# GD32C231 register map
File version: 1.0
GD32C231 ARM 32-bit Cortex-M23 Microcontroller based device
CPU: CM23 r0p0, little endian, MPU, FPU, 4 interrupt priority bits
Registers are 32-bit, read-write, reset 0x0 unless marked. A register's access mark holds for its fields unless they carry their own. Offsets are from the block's base; lines under a group give offsets from that group; [hi:lo] are bit positions; {n}, {i} and the like mark numbered series; 'fields as' and 'values as' point back to an identical list; <NAME> marks a mode.

## Memory map
0x40000400 TIMER2 size 0x400 — General-level0-timers
0x40002000 TIMER13 size 0x400 — General-level0-timers
0x40002800 RTC size 0x400 — Real time clock
0x40002C00 WWDGT size 0x400 — Window watchdog timer
0x40003000 FWDGT size 0x400 — free watchdog timer
0x40003800 SPI1 size 0x400 — Serial peripheral interface
0x40004400 USART1 size 0x400 — Universal synchronous asynchronous receiver transmitter
0x40004800 USART2 size 0x400 — Universal synchronous asynchronous receiver transmitter
0x40005400 I2C0 size 0x400 — Inter integrated circuit
0x40005800 I2C1 size 0x400
0x40007000 PMU size 0x400 — Power management unit
0x40010000 SYSCFG size 0x400 — System and memory architectur
0x40010400 EXTI size 0x400 — Interrupt / event controller
0x40012400 ADC size 0x400 — Analog-to-digital converter
0x40012C00 TIMER0 size 0x400 — Advanced-timers
0x40013000 SPI0 size 0x400 — Serial Peripheral Interface 0
0x40013800 USART0 size 0x400 — Universal synchronous asynchronous receiver transmitter
0x40014400 TIMER15 size 0x400 — General-level4-timers
0x40014800 TIMER16 size 0x400
0x40015800 DBGMCU size 0x400 — Debug support
0x40017C00 CMP size 0x400 — Comparator
0x40020000 DMA size 0x400 — DMA controller
0x40020800 DMAMUX size 0x400 — DMAMUX controller
0x40021000 RCU size 0x400 — Reset and clock unit
0x40022000 FMC size 0x400 — Flash memory controller
0x40023000 CRC size 0x400 — Cyclic redundancy checks management unit
0x48000000 GPIOA size 0x400 — General-purpose I/Os
0x48000400 GPIOB size 0x400 — General-purpose I/Os
0x48000800 GPIOC size 0x400
0x48000C00 GPIOD size 0x400
0x48001400 GPIOF size 0x400
0xE000E100 NVIC size 0xF00 — Nested Vectored Interrupt Controller

## Interrupts
0 WWDGT
1 RTC_Tamper_Timestamp (RTC)
2 RTC_WAKE (RTC)
3 FMC_GLOBAL (FMC)
4 RCU_CTC (RCU)
5 EXTI0 (EXTI)
6 EXTI01 (EXTI)
7 EXTI2 (EXTI)
8 EXTI3 (EXTI)
9 EXTI4 (EXTI)
10 DMA_Channel0 (DMA)
11 DMA_Channel1 (DMA)
12 DMA_Channel2 (DMA)
13 ADC
14 USART0
15 USART1
16 USART2
17 I2C0_EV (I2C0)
18 I2C0_ER (I2C0)
19 I2C1_EV (I2C1)
20 I2C1_ER (I2C1)
21 SPI0
22 SPI1
23 RTC_Alarm (RTC)
24 EXTI5_9 (EXTI)
25 TIMER0_TRIG_UP_BREAK (TIMER0)
26 TIMER0_CAP (TIMER0)
27 TIMER2
28 TIMER13
29 TIMER15
30 TIMER16
31 EXTI10_15 (EXTI)
33 DMA_MUX (DMAMUX)
34 CMP0 (CMP)
35 CMP1 (CMP)
36 I2C0_WAKE (I2C0)
37 I2C1_WAKE (I2C1)
38 USART0_WAKE (USART0)

## ADC — Analog-to-digital converter
Base 0x40012400
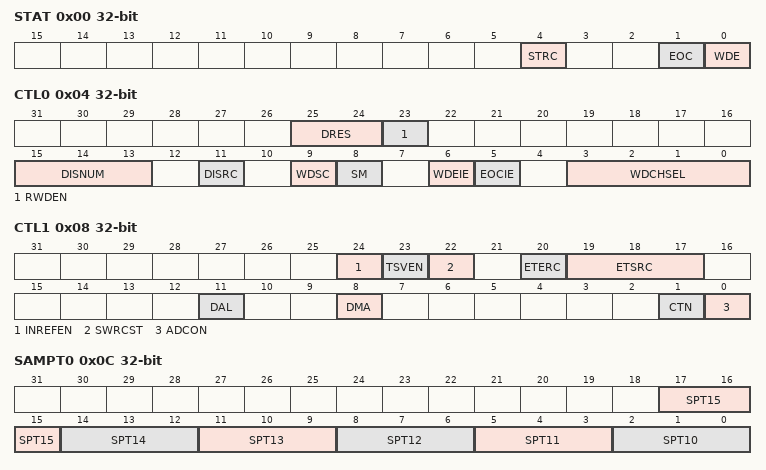
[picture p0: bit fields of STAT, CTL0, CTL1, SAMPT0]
0x00 STAT — Status register
  [4] STRC — Start flag of routine sequence
  [1] EOC — End flag of sequence conversion
  [0] WDE — Analog watchdog event flag
0x04 CTL0 — Control register 0
  [25:24] DRES — ADC resolution
  [23] RWDEN — Routine channel analog watchdog enable
  [15:13] DISNUM — Number of conversions in discontinuous mode
  [11] DISRC — Discontinuous mode on routine sequence
  [9] WDSC — When in scan mode, analog watchdog is effective on a single channel.
  [8] SM — Scan mode
  [6] WDEIE — Interrupt enable for WDE
  [5] EOCIE — Interrupt enable for EOC
  [3:0] WDCHSEL — Analog watchdog channel select
0x08 CTL1 — Control register 1
  [24] INREFEN — Channel 17 (internal reference voltage) enable of ADC.
  [23] TSVEN — Channel 16 (temperature sensor) enable of ADC.
  [22] SWRCST — Software start of routine sequence
  [20] ETERC — External trigger enable for routine sequence
  [19:17] ETSRC — External trigger selection for routine sequence
  [11] DAL — Data alignment
  [8] DMA — DMA request enable
  [1] CTN — Continuous mode
  [0] ADCON
0x0C SAMPT0 — Sample time register 0
  [3n-28:3n-30] SPT{n} (n=11..15) — Refer to SPT10[2:0] description.
  [2:0] SPT10 — Channel sample time
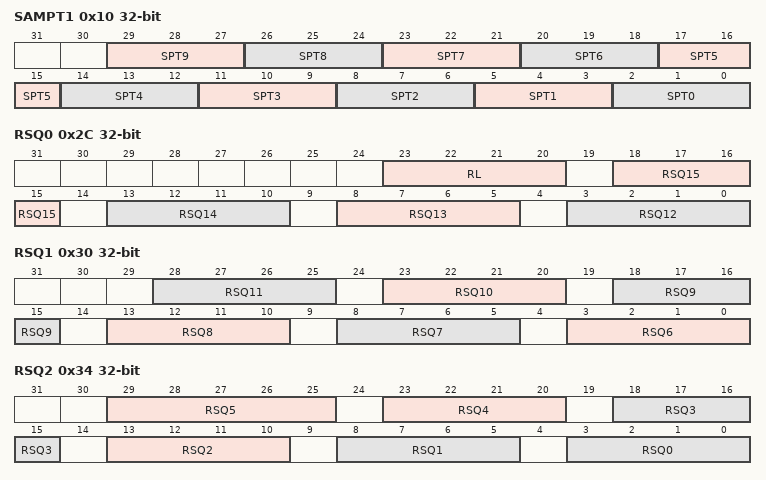
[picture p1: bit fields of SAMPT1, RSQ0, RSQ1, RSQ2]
0x10 SAMPT1 — Sample time register 1
  [3n+2:3n] SPT{n} (n=1..9) — Refer to SPT0[2:0] description
  [2:0] SPT0 — Channel sample time
0x24 WDHT reset 0xFFF — Watchdog high threshold register
  [11:0] WDHT — High threshold for analog watchdog
0x28 WDLT — Watchdog low threshold register
  [11:0] WDLT — Low threshold for analog watchdog
0x2C RSQ0 — Routine sequence register 0
  [23:20] RL — Routine sequence length
  [5n-57:5n-60] RSQ{n} (n=12..15) — Refer to RSQ0[3:0] description
0x30 RSQ1 — Routine sequence register 1
  [5n-27:5n-30] RSQ{n} (n=6..11) — Refer to RSQ0[3:0] description
0x34 RSQ2 — Routine sequence register 2
  [29:25] RSQ5 — Refer to RSQ0[3:0] description
  [5n+3:5n] RSQ{n} (n=1..4) — Refer to RSQ0[3:0] description
  [3:0] RSQ0 — The channel number (0..15) is written to these bits to select a channel as the nth conversion in the routine sequence.
0x4C RDATA ro — Routine data register
  [15:0] RDATA — Routine channel data
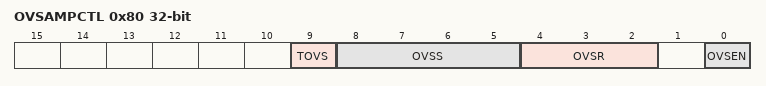
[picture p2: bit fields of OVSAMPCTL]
0x80 OVSAMPCTL — Oversample control register
  [9] TOVS — Triggered Oversampling
  [8:5] OVSS — Oversampling shift
  [4:2] OVSR — Oversampling ratio
  [0] OVSEN — Oversampler enable
